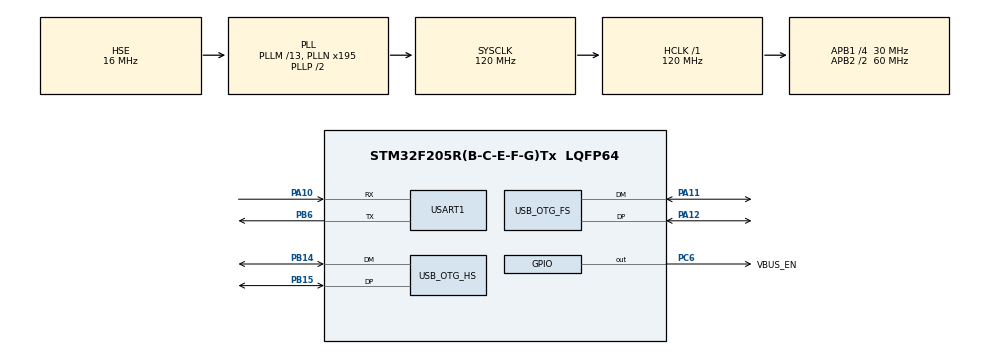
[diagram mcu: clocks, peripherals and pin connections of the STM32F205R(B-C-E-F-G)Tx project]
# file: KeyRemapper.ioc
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Mcu.Family=STM32F2
Mcu.Name=STM32F205R(B-C-E-F-G)Tx
Mcu.Package=LQFP64
NVIC.OTG_FS_IRQn=true\:8\:0\:true\:false\:true\:false\:true
NVIC.OTG_HS_IRQn=true\:0\:0\:false\:false\:true\:false\:true
NVIC.PriorityGroup=NVIC_PRIORITYGROUP_4
NVIC.TIM1_UP_TIM10_IRQn=true\:0\:0\:false\:false\:true\:false\:true
NVIC.TimeBase=TIM1_UP_TIM10_IRQn
NVIC.TimeBaseIP=TIM1
PA10.Mode=Asynchronous
PA10.Signal=USART1_RX
PA11.Mode=Host_Only
PA11.Signal=USB_OTG_FS_DM
PA12.Mode=Host_Only
PA12.Signal=USB_OTG_FS_DP
PA13.Mode=Serial_Wire
PA13.Signal=SYS_JTMS-SWDIO
PA14.Mode=Serial_Wire
PA14.Signal=SYS_JTCK-SWCLK
PB14.Mode=Device_Only_FS
PB14.Signal=USB_OTG_HS_DM
PB15.Mode=Device_Only_FS
PB15.Signal=USB_OTG_HS_DP
PB6.Mode=Asynchronous
PB6.Signal=USART1_TX
PC6.GPIO_Label=VBUS_EN
PC6.Signal=GPIO_Output
PH0-OSC_IN.Mode=HSE-External-Oscillator
PH0-OSC_IN.Signal=RCC_OSC_IN
PH1-OSC_OUT.Mode=HSE-External-Oscillator
PH1-OSC_OUT.Signal=RCC_OSC_OUT
ProjectManager.HeapSize=0x200
ProjectManager.StackSize=0x400
ProjectManager.TargetToolchain=STM32CubeIDE
RCC.48MHZClocksFreq_Value=48000000
RCC.AHBFreq_Value=120000000
RCC.APB1CLKDivider=RCC_HCLK_DIV4
RCC.APB1Freq_Value=30000000
RCC.APB1TimFreq_Value=60000000
RCC.APB2CLKDivider=RCC_HCLK_DIV2
RCC.APB2Freq_Value=60000000
RCC.APB2TimFreq_Value=120000000
RCC.CSICalibrationValue=16
RCC.CortexFreq_Value=120000000
RCC.ErrorLimitValue=34
RCC.Fsync=1000
RCC.HCLKFreq_Value=120000000
RCC.HSE_VALUE=16000000
RCC.HSI48CalibrationValue=32
RCC.HSI_VALUE=16000000
RCC.LSE_VALUE=32768
RCC.PLL1_VCI_Range=RCC_PLL1VCIRANGE_3
RCC.PLL1_VCO_SEL=RCC_PLL1VCOWIDE
RCC.PLL2FRACN=0
RCC.PLL2_VCI_Range=RCC_PLL2VCIRANGE_3
RCC.PLL2_VCO_SEL=RCC_PLL2VCOWIDE
RCC.PLL3FRACN=0
RCC.PLL3_VCI_Range=RCC_PLL3VCIRANGE_3
RCC.PLL3_VCO_SEL=RCC_PLL3VCOWIDE
RCC.PLLFRACN=0
RCC.PLLM=13
RCC.PLLN=195
RCC.PLLQ=5
RCC.PLLSourceVirtual=RCC_PLLSOURCE_HSE
RCC.PWR_Regulator_Voltage_Scale=PWR_REGULATOR_VOLTAGE_SCALE3
RCC.Polarity=RCC_CRS_SYNC_POLARITY_RISING
RCC.Prescaler=RCC_CRS_SYNC_DIV1
RCC.RCC_TIM_PRescaler_Selection=RCC_TIMPRES_DESACTIVATED
RCC.ReloadValue=__HAL_RCC_CRS_RELOADVALUE_CALCULATE(48000000,
RCC.ReloadValueARG=__HAL_RCC_CRS_RELOADVALUE_CALCULATE(48000000,1000)
RCC.ReloadValueType=automatic
RCC.SYSCLKFreq_VALUE=120000000
RCC.SYSCLKSource=RCC_SYSCLKSOURCE_PLLCLK
RCC.Source=RCC_CRS_SYNC_SOURCE_USB2
RCC.VCOOutputFreq_Value=240000000
USART1.VirtualMode=VM_ASYNC
USB_DEVICE.CLASS_NAME_HS=CUSTOM_HID
USB_DEVICE.CONFIGURATION_STRING_CUSTOMHID_HS=USB Keyboard Config
USB_DEVICE.INTERFACE_STRING_CUSTOMHID_HS=USB Keyboard Interface
USB_DEVICE.LANGID_STRING-CUSTOM_HID_HS=1033
USB_DEVICE.MANUFACTURER_STRING-CUSTOM_HID_HS=sa
USB_DEVICE.PID_CUSTOMHID_HS=10203
USB_DEVICE.PRODUCT_STRING_CUSTOMHID_HS=USB Keyboard
USB_DEVICE.VID-CUSTOM_HID_HS=5824
USB_DEVICE.VirtualMode-CUSTOM_HID_HS=CustomHid
USB_DEVICE.VirtualModeHS=Custom_Hid_HS
USB_HOST.BSP.number=1
USB_HOST.USBH_DEBUG_LEVEL-HID_FS=0
USB_HOST.USBH_HandleTypeDef-HID_FS=hUsbHostFS
USB_HOST.USBH_PROCESS_STACK_SIZE-HID_FS=256
USB_HOST.USBH_USE_OS-HID_FS=0
USB_HOST.VirtualModeFS=Hid
USB_HOST0.BSP.STBoard=false
USB_HOST0.BSP.api=Unknown
USB_HOST0.BSP.i2caddr=0
USB_HOST0.BSP.instance=PC6
USB_HOST0.BSP.ip=GPIO
USB_HOST0.BSP.mode=Output
USB_HOST0.BSP.name=Drive_VBUS_FS
USB_HOST0.BSP.solution=PC6
USB_OTG_FS.Sof_enable=ENABLE
USB_OTG_FS.VirtualMode=Host_Only
USB_OTG_FS.phy_itface=HCD_PHY_EMBEDDED
USB_OTG_FS.speed=HCD_SPEED_FULL
USB_OTG_HS.VirtualMode-Device_Only_FS=Device_Only_FS
VP_SYS_VS_tim1.Mode=TIM1
VP_USB_DEVICE_VS_USB_DEVICE_CUSTOM_HID_HS.Mode=CUSTOM_HID_HS
VP_USB_HOST_VS_USB_HOST_HID_FS.Mode=HID_FS
board=custom

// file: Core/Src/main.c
/* USER CODE BEGIN Header */
/**
  ******************************************************************************
  * @file           : main.c
  * @brief          : Main program body
  ******************************************************************************
  * @attention
  *
  * <h2><center>&copy; Copyright (c) 2019 STMicroelectronics.
  * All rights reserved.</center></h2>
  *
  * This software component is licensed by ST under BSD 3-Clause license,
  * the "License"; You may not use this file except in compliance with the
  * License. You may obtain a copy of the License at:
  *                        opensource.org/licenses/BSD-3-Clause
  *
  ******************************************************************************
  */
/* USER CODE END Header */

#include "main.h"
#include "usb_device.h"
#include "usb_host.h"

/* USER CODE BEGIN Includes */
#include "KeyRemapper.h"
/* USER CODE END Includes */

UART_HandleTypeDef huart1;

void SystemClock_Config(void);
static void MX_GPIO_Init(void);
static void MX_USART1_UART_Init(void);
void MX_USB_HOST_Process(void);

int main(void)
{

  /* MCU Configuration--------------------------------------------------------*/

  /* Reset of all peripherals, Initializes the Flash interface and the Systick. */
  HAL_Init();

  /* Configure the system clock */
  SystemClock_Config();

  /* Initialize all configured peripherals */
  MX_GPIO_Init();
  MX_USART1_UART_Init();
  MX_USB_HOST_Init();
  MX_USB_DEVICE_Init();

  /* Infinite loop */
  /* USER CODE BEGIN WHILE */
  int i=0;
  while (1)
  {
    /* USER CODE END WHILE */
    MX_USB_HOST_Process();

    /* USER CODE BEGIN 3 */
	updateLedState();
  }
  /* USER CODE END 3 */
}

void SystemClock_Config(void)
{
  RCC_OscInitTypeDef RCC_OscInitStruct = {0};
  RCC_ClkInitTypeDef RCC_ClkInitStruct = {0};

  /** Initializes the CPU, AHB and APB busses clocks
  */
  RCC_OscInitStruct.OscillatorType = RCC_OSCILLATORTYPE_HSE;
  RCC_OscInitStruct.HSEState = RCC_HSE_ON;
  RCC_OscInitStruct.PLL.PLLState = RCC_PLL_ON;
  RCC_OscInitStruct.PLL.PLLSource = RCC_PLLSOURCE_HSE;
  RCC_OscInitStruct.PLL.PLLM = 13;
  RCC_OscInitStruct.PLL.PLLN = 195;
  RCC_OscInitStruct.PLL.PLLP = RCC_PLLP_DIV2;
  RCC_OscInitStruct.PLL.PLLQ = 5;
  if (HAL_RCC_OscConfig(&RCC_OscInitStruct) != HAL_OK)
  {
    Error_Handler();
  }
  /** Initializes the CPU, AHB and APB busses clocks
  */
  RCC_ClkInitStruct.ClockType = RCC_CLOCKTYPE_HCLK|RCC_CLOCKTYPE_SYSCLK
                              |RCC_CLOCKTYPE_PCLK1|RCC_CLOCKTYPE_PCLK2;
  RCC_ClkInitStruct.SYSCLKSource = RCC_SYSCLKSOURCE_PLLCLK;
  RCC_ClkInitStruct.AHBCLKDivider = RCC_SYSCLK_DIV1;
  RCC_ClkInitStruct.APB1CLKDivider = RCC_HCLK_DIV4;
  RCC_ClkInitStruct.APB2CLKDivider = RCC_HCLK_DIV2;

  if (HAL_RCC_ClockConfig(&RCC_ClkInitStruct, FLASH_LATENCY_3) != HAL_OK)
  {
    Error_Handler();
  }
}

static void MX_USART1_UART_Init(void)
{

  huart1.Instance = USART1;
  huart1.Init.BaudRate = 115200;
  huart1.Init.WordLength = UART_WORDLENGTH_8B;
  huart1.Init.StopBits = UART_STOPBITS_1;
  huart1.Init.Parity = UART_PARITY_NONE;
  huart1.Init.Mode = UART_MODE_TX_RX;
  huart1.Init.HwFlowCtl = UART_HWCONTROL_NONE;
  huart1.Init.OverSampling = UART_OVERSAMPLING_16;
  if (HAL_UART_Init(&huart1) != HAL_OK)
  {
    Error_Handler();
  }

}

static void MX_GPIO_Init(void)
{
  GPIO_InitTypeDef GPIO_InitStruct = {0};

  /* GPIO Ports Clock Enable */
  __HAL_RCC_GPIOH_CLK_ENABLE();
  __HAL_RCC_GPIOB_CLK_ENABLE();
  __HAL_RCC_GPIOC_CLK_ENABLE();
  __HAL_RCC_GPIOA_CLK_ENABLE();

  /*Configure GPIO pin Output Level */
  HAL_GPIO_WritePin(VBUS_EN_GPIO_Port, VBUS_EN_Pin, GPIO_PIN_RESET);

  /*Configure GPIO pin : VBUS_EN_Pin */
  GPIO_InitStruct.Pin = VBUS_EN_Pin;
  GPIO_InitStruct.Mode = GPIO_MODE_OUTPUT_PP;
  GPIO_InitStruct.Pull = GPIO_NOPULL;
  GPIO_InitStruct.Speed = GPIO_SPEED_FREQ_LOW;
  HAL_GPIO_Init(VBUS_EN_GPIO_Port, &GPIO_InitStruct);

}

void HAL_TIM_PeriodElapsedCallback(TIM_HandleTypeDef *htim)
{
  if (htim->Instance == TIM1) {
    HAL_IncTick();
  }
}

void Error_Handler(void)
{
}

/************************ (C) COPYRIGHT STMicroelectronics *****END OF FILE****/
